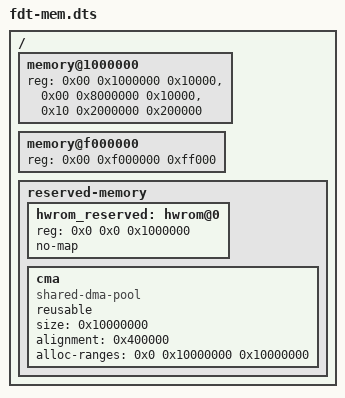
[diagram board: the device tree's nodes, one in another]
/dts-v1/;

/ {
    #address-cells = <2>;
    #size-cells = <1>;

    memory@1000000 {
        device_type = "memory";

        reg = <0x00 0x1000000 0x10000 >,
              <0x00 0x8000000 0x10000 >,
              <0x10 0x2000000 0x200000 >;
    };

    memory@f000000 {
        device_type = "memory";

        reg = <0x00 0xf000000 0xff000 >;
    };

    reserved-memory {
        #address-cells = <2>;
        #size-cells = <1>;
        ranges;

        hwrom_reserved: hwrom@0 {
            reg = <0x0 0x0 0x1000000>;
            no-map;
        };

        cma {
            compatible = "shared-dma-pool";
            reusable;
            size = <0x10000000>;
            alignment = <0x400000>;
            alloc-ranges = <0x0 0x10000000 0x10000000>;
        };
    };
};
